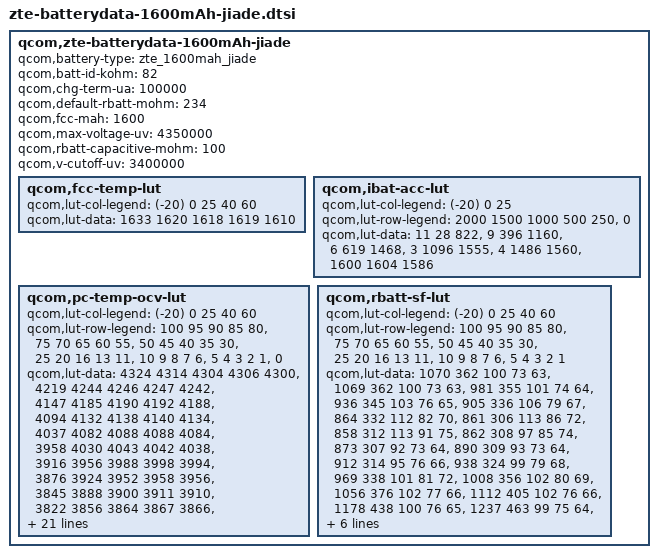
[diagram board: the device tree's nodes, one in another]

qcom,zte-batterydata-1600mAh-jiade {
	qcom,battery-type = "zte_1600mah_jiade";
	qcom,batt-id-kohm = <82>;
	qcom,chg-term-ua = <100000>;
	qcom,default-rbatt-mohm = <234>;
	qcom,fcc-mah = <1600>;
	qcom,max-voltage-uv = <4350000>;
	qcom,rbatt-capacitive-mohm = <100>;
	qcom,v-cutoff-uv = <3400000>;

	qcom,fcc-temp-lut {
		qcom,lut-col-legend = <(-20) 0 25 40 60>;
		qcom,lut-data = <1633 1620 1618 1619 1610>;
	};

	qcom,ibat-acc-lut {
		qcom,lut-col-legend = <(-20) 0 25>;
		qcom,lut-row-legend = <2000 1500 1000 500 250>,
					<0>;
		qcom,lut-data = <11 28 822>,
				<9 396 1160>,
				<6 619 1468>,
				<3 1096 1555>,
				<4 1486 1560>,
				<1600 1604 1586>;
	};

	qcom,pc-temp-ocv-lut {
		qcom,lut-col-legend = <(-20) 0 25 40 60>;
		qcom,lut-row-legend = <100 95 90 85 80>,
					<75 70 65 60 55>,
					<50 45 40 35 30>,
					<25 20 16 13 11>,
					<10 9 8 7 6>,
					<5 4 3 2 1>,
					<0>;
		qcom,lut-data = <4324 4314 4304 4306 4300>,
				<4219 4244 4246 4247 4242>,
				<4147 4185 4190 4192 4188>,
				<4094 4132 4138 4140 4134>,
				<4037 4082 4088 4088 4084>,
				<3958 4030 4043 4042 4038>,
				<3916 3956 3988 3998 3994>,
				<3876 3924 3952 3958 3956>,
				<3845 3888 3900 3911 3910>,
				<3822 3856 3864 3867 3866>,
				<3805 3828 3838 3840 3839>,
				<3790 3806 3816 3818 3817>,
				<3774 3788 3798 3800 3799>,
				<3760 3776 3782 3783 3782>,
				<3744 3762 3768 3768 3760>,
				<3728 3747 3752 3748 3734>,
				<3708 3731 3734 3728 3714>,
				<3689 3718 3711 3706 3691>,
				<3672 3708 3694 3688 3674>,
				<3660 3701 3690 3683 3670>,
				<3652 3696 3688 3682 3669>,
				<3642 3692 3686 3681 3668>,
				<3630 3686 3684 3679 3666>,
				<3615 3680 3678 3676 3660>,
				<3596 3667 3658 3663 3642>,
				<3572 3644 3618 3630 3607>,
				<3540 3605 3565 3583 3560>,
				<3492 3550 3496 3523 3500>,
				<3417 3470 3406 3440 3422>,
				<3269 3346 3295 3310 3297>,
				<3000 3000 3040 3000 3000>;
	};

	qcom,rbatt-sf-lut {
		qcom,lut-col-legend = <(-20) 0 25 40 60>;
		qcom,lut-row-legend = <100 95 90 85 80>,
					<75 70 65 60 55>,
					<50 45 40 35 30>,
					<25 20 16 13 11>,
					<10 9 8 7 6>,
					<5 4 3 2 1>;
		qcom,lut-data = <1070 362 100 73 63>,
				<1069 362 100 73 63>,
				<981 355 101 74 64>,
				<936 345 103 76 65>,
				<905 336 106 79 67>,
				<864 332 112 82 70>,
				<861 306 113 86 72>,
				<858 312 113 91 75>,
				<862 308 97 85 74>,
				<873 307 92 73 64>,
				<890 309 93 73 64>,
				<912 314 95 76 66>,
				<938 324 99 79 68>,
				<969 338 101 81 72>,
				<1008 356 102 80 69>,
				<1056 376 102 77 66>,
				<1112 405 102 76 66>,
				<1178 438 100 76 65>,
				<1237 463 99 75 64>,
				<1199 440 99 74 65>,
				<1280 450 101 76 66>,
				<1370 465 104 78 67>,
				<1476 481 109 80 68>,
				<1602 497 112 83 69>,
				<1772 515 109 82 67>,
				<1995 533 107 78 66>,
				<2300 559 112 79 68>,
				<2796 599 119 83 72>,
				<3710 653 139 93 79>,
				<7421 1088 278 141 91>;
	};
};
/* TEST_DB_ID=TEST_ID_NOT_SET */

